# SIM3U167_B register map
File version: 1
CPU: 
Registers are 32-bit, read-write, reset 0x0 unless marked. A register's access mark holds for its fields unless they carry their own. Offsets are from the block's base; [hi:lo] are bit positions.

## CLKCTRL_0
Base 0x4002D000
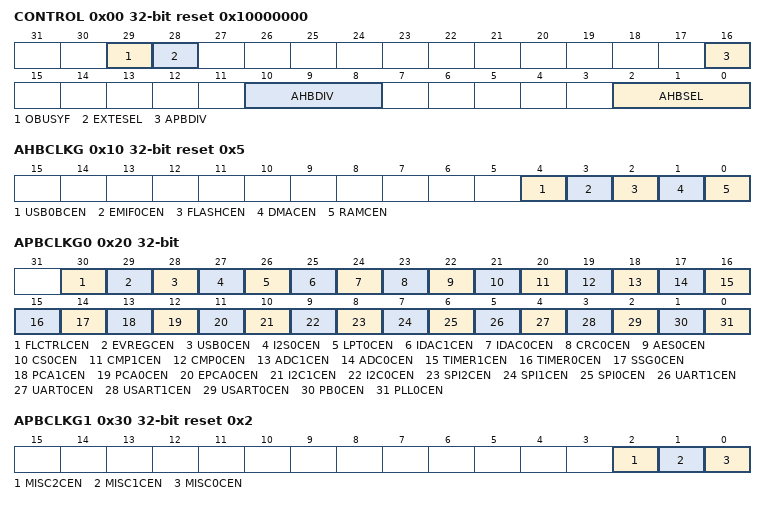
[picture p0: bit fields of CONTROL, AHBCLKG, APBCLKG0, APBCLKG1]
0x00 CONTROL reset 0x10000000 — Module Control
  [29] OBUSYF ro — Oscillators Busy Flag.
    0=NOT_SET (AHB and APB oscillators are not busy.); 1=SET (AHB and APB oscillators are busy and the AHBSEL, AHBDIV, and APBDIV fields should not be modified.)
  [28] EXTESEL — External Clock Edge Select.
    0=BOTH_EDGES (External clock generated by both rising and falling edges of the external oscillator.); 1=RISING_ONLY (External clock generated by only rising edges of the external oscillator.)
  [16] APBDIV — APB Clock Divider.
    0=DIV1 (APB clock is the same as the AHB clock (divided by 1).); 1=DIV2 (APB clock is the AHB clock divided by 2.)
  [10:8] AHBDIV — AHB Clock Divider.
    0=DIV1 (AHB clock divided by 1.); 1=DIV2 (AHB clock divided by 2.); 2=DIV4 (AHB clock divided by 4.); 3=DIV8 (AHB clock divided by 8.); 4=DIV16 (AHB clock divided by 16.); 5=DIV32 (AHB clock divided by 32.); 6=DIV64 (AHB clock divided by 64.); 7=DIV128 (AHB clock divided by 128.)
  [2:0] AHBSEL — AHB Clock Source Select.
    0=LPOSC0 (AHB clock source is the Low-Power Oscillator.); 1=LFOSC0 (AHB clock source is the Low-Frequency Oscillator.); 2=RTC0OSC (AHB clock source is the RTC Oscillator.); 3=EXTOSC0 (AHB clock source is the External Oscillator.); 4=USB0OSC (AHB clock source is the USB Oscillator.); 5=PLL0OSC (AHB clock source is the PLL.); 6=LPOSC0_DIV (AHB clock source is a divided version of the Low-Power Oscillator.)
0x10 AHBCLKG reset 0x5 — AHB Clock Gate
  [4] USB0BCEN — USB0 Buffer Clock Enable.
    0=DISABLED (Disable the AHB clock to the USB0 Buffer (default).); 1=ENABLED (Enable the AHB clock to the USB0 Buffer.)
  [3] EMIF0CEN — EMIF Clock Enable.
    0=DISABLED (Disable the AHB clock to the External Memory Interface (EMIF) (default).); 1=ENABLED (Enable the AHB clock to the External Memory Interface (EMIF).)
  [2] FLASHCEN — Flash Clock Enable.
    0=DISABLED (Disable the AHB clock to the Flash.); 1=ENABLED (Enable the AHB clock to the Flash (default).)
  [1] DMACEN — DMA Controller Clock Enable.
    0=DISABLED (Disable the AHB clock to the DMA Controller (default).); 1=ENABLED (Enable the AHB clock to the DMA Controller.)
  [0] RAMCEN — RAM Clock Enable.
    0=DISABLED (Disable the AHB clock to the RAM.); 1=ENABLED (Enable the AHB clock to the RAM (default).)
0x20 APBCLKG0 — APB Clock Gate 0
  [30] FLCTRLCEN — Flash Controller Clock Enable.
    0=DISABLED (Disable the APB clock to the Flash Controller Module (FLASHCTRL0) (default).); 1=ENABLED (Enable the APB clock to the Flash Controller Module (FLASHCTRL0).)
  [29] EVREGCEN — External Regulator Clock Enable.
    0=DISABLED (Disable the APB clock to the External Regulator Module (EXTVREG0) (default).); 1=ENABLED (Enable the APB clock to the External Regulator Module (EXTVREG0).)
  [28] USB0CEN — USB0 Module Clock Enable.
    0=DISABLED (Disable the APB clock to the USB0 Module (default).); 1=ENABLED (Enable the APB clock to the USB0 Module.)
  [27] I2S0CEN — I2S0 Module Clock Enable.
    0=DISABLED (Disable the APB clock to the I2S0 Module (default).); 1=ENABLED (Enable the APB clock to the I2S0 Module.)
  [26] LPT0CEN — Low Power Timer (LPTIMER0) Module Clock Enable.
    0=DISABLED (Disable the APB clock to the LPTIMER0 Module (default).); 1=ENABLED (Enable the APB clock to the LPTIMER0 Module.)
  [25] IDAC1CEN — IDAC1 Module Clock Enable.
    0=DISABLED (Disable the APB clock to the IDAC1 Module (default).); 1=ENABLED (Enable the APB clock to the IDAC1 Module.)
  [24] IDAC0CEN — IDAC0 Module Clock Enable.
    0=DISABLED (Disable the APB clock to the IDAC0 Module (default).); 1=ENABLED (Enable the APB clock to the IDAC0 Module.)
  [23] CRC0CEN — CRC0 Module Clock Enable.
    0=DISABLED (Disable the APB clock to the CRC0 Module (default).); 1=ENABLED (Enable the APB clock to the CRC0 Module.)
  [22] AES0CEN — AES0 Module Clock Enable.
    0=DISABLED (Disable the APB clock to the AES0 Module (default).); 1=ENABLED (Enable the APB clock to the AES0 Module.)
  [21] CS0CEN — Capacitive Sensing (CAPSENSE0) Module Clock Enable.
    0=DISABLED (Disable the APB clock to the CAPSENSE0 Module (default).); 1=ENABLED (Enable the APB clock to the CAPSENSE0 Module.)
  [20] CMP1CEN — Comparator 1 Module Clock Enable.
    0=DISABLED (Disable the APB clock to the Comparator 1 Module (default).); 1=ENABLED (Enable the APB clock to the Comparator 1 Module.)
  [19] CMP0CEN — Comparator 0 Module Clock Enable.
    0=DISABLED (Disable the APB clock to the Comparator 0 Module (default).); 1=ENABLED (Enable the APB clock to the Comparator 0 Module.)
  [18] ADC1CEN — SARADC1 Module Clock Enable.
    0=DISABLED (Disable the APB clock to the SARADC1 Module (default).); 1=ENABLED (Enable the APB clock to the SARADC1 Module.)
  [17] ADC0CEN — SARADC0 Module Clock Enable.
    0=DISABLED (Disable the APB clock to the SARADC0 Module (default).); 1=ENABLED (Enable the APB clock to the SARADC0 Module.)
  [16] TIMER1CEN — TIMER1 Module Clock Enable.
    0=DISABLED (Disable the APB clock to the TIMER1 Module (default).); 1=ENABLED (Enable the APB clock to the TIMER1 Module.)
  [15] TIMER0CEN — TIMER0 Module Clock Enable.
    0=DISABLED (Disable the APB clock to the TIMER0 Module (default).); 1=ENABLED (Enable the APB clock to the TIMER0 Module.)
  [14] SSG0CEN — SSG0 Module Clock Enable.
    0=DISABLED (Disable the APB clock to the SSG0 Module (default).); 1=ENABLED (Enable the APB clock to the SSG0 Module.)
  [13] PCA1CEN — PCA1 Module Clock Enable.
    0=DISABLED (Disable the APB clock to the PCA1 Module (default).); 1=ENABLED (Enable the APB clock to the PCA1 Module.)
  [12] PCA0CEN — PCA0 Module Clock Enable.
    0=DISABLED (Disable the APB clock to the PCA0 Module (default).); 1=ENABLED (Enable the APB clock to the PCA0 Module.)
  [11] EPCA0CEN — EPCA0 Module Clock Enable.
    0=DISABLED (Disable the APB clock to the EPCA0 Module (default).); 1=ENABLED (Enable the APB clock to the EPCA0 Module.)
  [10] I2C1CEN — I2C1 Module Clock Enable.
    0=DISABLED (Disable the APB clock to the I2C1 Module (default).); 1=ENABLED (Enable the APB clock to the I2C1 Module.)
  [9] I2C0CEN — I2C0 Module Clock Enable.
    0=DISABLED (Disable the APB clock to the I2C0 Module (default).); 1=ENABLED (Enable the APB clock to the I2C0 Module.)
  [8] SPI2CEN — SPI2 Module Clock Enable.
    0=DISABLED (Disable the APB clock to the SPI2 Module (default).); 1=ENABLED (Enable the APB clock to the SPI2 Module.)
  [7] SPI1CEN — SPI1 Module Clock Enable.
    0=DISABLED (Disable the APB clock to the SPI1 Module (default).); 1=ENABLED (Enable the APB clock to the SPI1 Module.)
  [6] SPI0CEN — SPI0 Module Clock Enable.
    0=DISABLED (Disable the APB clock to the SPI0 Module (default).); 1=ENABLED (Enable the APB clock to the SPI0 Module.)
  [5] UART1CEN — UART1 Module Clock Enable.
    0=DISABLED (Disable the APB clock to the UART1 Module (default).); 1=ENABLED (Enable the APB clock to the UART1 Module.)
  [4] UART0CEN — UART0 Module Clock Enable.
    0=DISABLED (Disable the APB clock to the UART0 Module (default).); 1=ENABLED (Enable the APB clock to the UART0 Module.)
  [3] USART1CEN — USART1 Module Clock Enable.
    0=DISABLED (Disable the APB clock to the USART1 Module (default).); 1=ENABLED (Enable the APB clock to the USART1 Module.)
  [2] USART0CEN — USART0 Module Clock Enable.
    0=DISABLED (Disable the APB clock to the USART0 Module (default).); 1=ENABLED (Enable the APB clock to the USART0 Module.)
  [1] PB0CEN — Port Bank Module Clock Enable.
    0=DISABLED (Disable the APB clock to the Port Bank Modules (default).); 1=ENABLED (Enable the APB clock to the Port Bank Modules.)
  [0] PLL0CEN — PLL Module Clock Enable.
    0=DISABLED (Disable the APB clock to the PLL0 registers (default).); 1=ENABLED (Enable the APB clock to the PLL0 registers.)
0x30 APBCLKG1 reset 0x2 — APB Clock Gate 1
  [2] MISC2CEN — Miscellaneous 2 Clock Enable.
    0=DISABLED (Disable the APB clock to the OSCVLDF flag in the EXTOSC module (default).); 1=ENABLED (Enable the APB clock to the OSCVLDF flag in the EXTOSC module.)
  [1] MISC1CEN — Miscellaneous 1 Clock Enable.
    0=DISABLED (Disable the APB clock to the Watchdog Timer (WDTIMER0), EMIF0, and DMA Crossbar (DMAXBAR0) modules.); 1=ENABLED (Enable the APB clock to the Watchdog Timer (WDTIMER0), EMIF0, and DMA Crossbar (DMAXBAR0) modules (default).)
  [0] MISC0CEN — Miscellaneous 0 Clock Enable.
    0=DISABLED (Disable the APB clock to the RSTSRC0, LOCK0, VMON0, VREG0, LDO0, VREF0, EXTOSC0, LPOSC0, EXTVREG0, IVC0 and RTC0 modules (default).); 1=ENABLED (Enable the APB clock to the RSTSRC0, LOCK0, VMON0, VREG0, LDO0, VREF0, EXTOSC0, LPOSC0, EXTVREG0, IVC0 and RTC0 modules.)
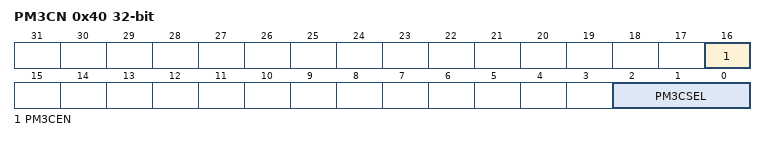
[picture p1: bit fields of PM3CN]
0x40 PM3CN — Power Mode 3 Clock Control
  [16] PM3CEN — Power Mode 3 Fast-Wake Clock Enable.
    0=DISABLED (Disable the core clock when in Power Mode 3.); 1=ENABLED (The core clock is enabled and runs off the clock selected by PM3CSEL in Power Mode 3.)
  [2:0] PM3CSEL — Power Mode 3 Fast-Wake Clock Source.
    0=LPOSC0 (Power Mode 3 clock source is the Low-Power Oscillator.); 1=LFOSC0 (Power Mode 3 clock source is the Low-Frequency Oscillator.); 2=RTC0OSC (Power Mode 3 clock source is the RTC Oscillator.); 3=EXTOSC0 (Power Mode 3 clock source is the External Oscillator.); 4=USB0OSC (Power Mode 3 clock source is the USB Oscillator.); 5=PLL0OSC (Power Mode 3 clock source is the PLL.); 6=LPOSC0_DIV (Power Mode 3 clock source is a divided version of the Low-Power Oscillator.)
